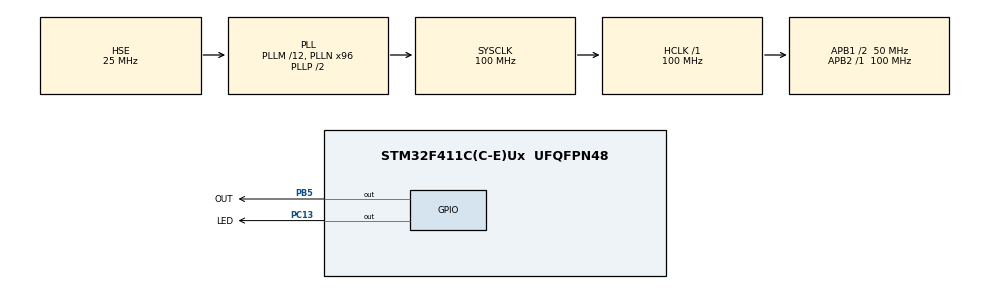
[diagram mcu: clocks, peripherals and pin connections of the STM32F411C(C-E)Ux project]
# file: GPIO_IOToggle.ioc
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Mcu.Family=STM32F4
Mcu.Name=STM32F411C(C-E)Ux
Mcu.Package=UFQFPN48
NVIC.PriorityGroup=NVIC_PRIORITYGROUP_4
PA13.Mode=Serial_Wire
PA13.Signal=SYS_JTMS-SWDIO
PA14.Mode=Serial_Wire
PA14.Signal=SYS_JTCK-SWCLK
PB5.GPIO_Label=OUT
PB5.GPIO_PuPd=GPIO_PULLUP
PB5.Signal=GPIO_Output
PC13-ANTI_TAMP.GPIO_Label=LED
PC13-ANTI_TAMP.GPIO_PuPd=GPIO_PULLUP
PC13-ANTI_TAMP.GPIO_Speed=GPIO_SPEED_FREQ_LOW
PC13-ANTI_TAMP.Signal=GPIO_Output
PH0\ -\ OSC_IN.Mode=HSE-External-Oscillator
PH0\ -\ OSC_IN.Signal=RCC_OSC_IN
PH1\ -\ OSC_OUT.Mode=HSE-External-Oscillator
PH1\ -\ OSC_OUT.Signal=RCC_OSC_OUT
ProjectManager.HeapSize=0x200
ProjectManager.StackSize=0x400
ProjectManager.TargetToolchain=MDK-ARM V5.27
RCC.48MHZClocksFreq_Value=50000000
RCC.AHBFreq_Value=100000000
RCC.APB1CLKDivider=RCC_HCLK_DIV2
RCC.APB1Freq_Value=50000000
RCC.APB1TimFreq_Value=100000000
RCC.APB2Freq_Value=100000000
RCC.APB2TimFreq_Value=100000000
RCC.CortexFreq_Value=100000000
RCC.EnbaleCSS=true
RCC.HCLKFreq_Value=100000000
RCC.HSE_VALUE=25000000
RCC.HSI_VALUE=16000000
RCC.LSE_VALUE=32768
RCC.PLLM=12
RCC.PLLN=96
RCC.PLLSourceVirtual=RCC_PLLSOURCE_HSE
RCC.SYSCLKFreq_VALUE=100000000
RCC.SYSCLKSource=RCC_SYSCLKSOURCE_PLLCLK
RCC.VCOOutputFreq_Value=200000000
board=custom

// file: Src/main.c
/* USER CODE BEGIN Header */
/**
  ******************************************************************************
  * @file           : main.c
  * @brief          : Main program body
  ******************************************************************************
  * @attention
  *
  * <h2><center>&copy; Copyright (c) 2020 STMicroelectronics.
  * All rights reserved.</center></h2>
  *
  * This software component is licensed by ST under BSD 3-Clause license,
  * the "License"; You may not use this file except in compliance with the
  * License. You may obtain a copy of the License at:
  *                        opensource.org/licenses/BSD-3-Clause
  *
  ******************************************************************************
  */
/* USER CODE END Header */

#include "main.h"
#include "gpio.h"

void SystemClock_Config(void);

/* USER CODE BEGIN 0 */
 /*
  *power by WeAct Studio
  *The board with `WeAct` Logo && `version number` is our board, quality guarantee.
  *For more information please visit: https://github.com/WeActTC/MiniF4-STM32F4x1
  *更多信息请访问：https://gitee.com/WeActTC/MiniF4-STM32F4x1
  */
/* USER CODE END 0 */

int main(void)
{

  /* MCU Configuration--------------------------------------------------------*/

  /* Reset of all peripherals, Initializes the Flash interface and the Systick. */
  HAL_Init();

  /* Configure the system clock */
  SystemClock_Config();

  /* Initialize all configured peripherals */
  MX_GPIO_Init();

  /* Infinite loop */
  /* USER CODE BEGIN WHILE */
  while (1)
  {
		/* you should write your code here(between "BEGIN" and "END") */
		/* 你应该把你的代码写在这里(在BEGIN与END之间) */
		HAL_GPIO_TogglePin(LED_GPIO_Port, LED_Pin);		//toggle the pin
		HAL_Delay(500);

		/* You can also write this, uncomment the code below and then comment the code above */
		/* 或�?�你可以这样写，把下面的代码反注释然后把上面的代码注�? */
//		HAL_GPIO_WritePin(LED_GPIO_Port, LED_Pin, GPIO_PIN_RESET);
//		HAL_Delay(500);
//		HAL_GPIO_WritePin(LED_GPIO_Port, LED_Pin, GPIO_PIN_SET);
//		HAL_Delay(500);
    /* USER CODE END WHILE */

  }
}

void SystemClock_Config(void)
{
  RCC_OscInitTypeDef RCC_OscInitStruct = {0};
  RCC_ClkInitTypeDef RCC_ClkInitStruct = {0};

  /** Configure the main internal regulator output voltage
  */
  __HAL_RCC_PWR_CLK_ENABLE();
  __HAL_PWR_VOLTAGESCALING_CONFIG(PWR_REGULATOR_VOLTAGE_SCALE1);
  /** Initializes the CPU, AHB and APB busses clocks
  */
  RCC_OscInitStruct.OscillatorType = RCC_OSCILLATORTYPE_HSE;
  RCC_OscInitStruct.HSEState = RCC_HSE_ON;
  RCC_OscInitStruct.PLL.PLLState = RCC_PLL_ON;
  RCC_OscInitStruct.PLL.PLLSource = RCC_PLLSOURCE_HSE;
  RCC_OscInitStruct.PLL.PLLM = 12;
  RCC_OscInitStruct.PLL.PLLN = 96;
  RCC_OscInitStruct.PLL.PLLP = RCC_PLLP_DIV2;
  RCC_OscInitStruct.PLL.PLLQ = 4;
  if (HAL_RCC_OscConfig(&RCC_OscInitStruct) != HAL_OK)
  {
    Error_Handler();
  }
  /** Initializes the CPU, AHB and APB busses clocks
  */
  RCC_ClkInitStruct.ClockType = RCC_CLOCKTYPE_HCLK|RCC_CLOCKTYPE_SYSCLK
                              |RCC_CLOCKTYPE_PCLK1|RCC_CLOCKTYPE_PCLK2;
  RCC_ClkInitStruct.SYSCLKSource = RCC_SYSCLKSOURCE_PLLCLK;
  RCC_ClkInitStruct.AHBCLKDivider = RCC_SYSCLK_DIV1;
  RCC_ClkInitStruct.APB1CLKDivider = RCC_HCLK_DIV2;
  RCC_ClkInitStruct.APB2CLKDivider = RCC_HCLK_DIV1;

  if (HAL_RCC_ClockConfig(&RCC_ClkInitStruct, FLASH_LATENCY_3) != HAL_OK)
  {
    Error_Handler();
  }
  /** Enables the Clock Security System
  */
  HAL_RCC_EnableCSS();
}

void Error_Handler(void)
{
}

/************************ (C) COPYRIGHT STMicroelectronics *****END OF FILE****/
